# WKUPAON_PRM register map
Vendor: Texas Instruments
Peripheral module from a debugger description file (folder omap5430_ES2_PUBLIC).
Registers are 32-bit, access not given, reset 0x1 unless marked. A register's access mark holds for its fields unless they carry their own. Offsets are as the file gives them; lines under a group give offsets from that group; [hi:lo] are bit positions; {n}, {i} and the like mark numbered series; 'fields as' and 'values as' point back to an identical list; <NAME> marks a mode.

## WKUPAON_PRM
0x24 RM_WKUPAON_L4_WKUP_CONTEXT — This register contains dedicated L4_WKUP context statuses. [warm reset insensitive]
  [0] LOSTCONTEXT_DFF — Specify if DFF-based context has been lost due to a previous power transition or other reset source. (set upon assertion of WKUPAON_RST signal) (access RW W1toClr)
    0=Maintained (Context has been maintained); 1=Lost (Context has been lost)
0x30 PM_WKUPAON_WD_TIMER2_WKDEP access per field reset 0x0 — This register controls wakeup dependency based on WD_TIMER2 service requests.
  [0] WKUPDEP_WD_TIMER2_MPU rw — Wakeup dependency from WD_TIMER2 module (SWakeup signal) towards MPU + L3_MAIN1 domains
    0=Disabled (Dependency is disabled); 1=Enabled (Dependency is enabled)
0x34 RM_WKUPAON_WD_TIMER2_CONTEXT — This register contains dedicated WD_TIMER2 context statuses. [warm reset insensitive]
  fields as RM_WKUPAON_L4_WKUP_CONTEXT
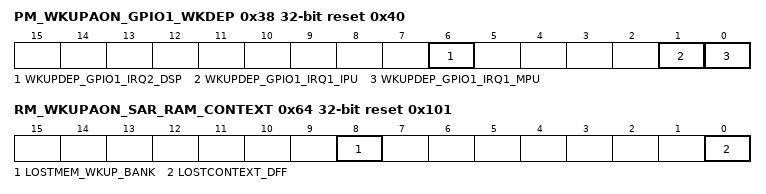
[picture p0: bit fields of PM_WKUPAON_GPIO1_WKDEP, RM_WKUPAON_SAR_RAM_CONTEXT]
0x38 PM_WKUPAON_GPIO1_WKDEP access per field reset 0x40 — This register controls wakeup dependency based on GPIO1 service requests.
  [6] WKUPDEP_GPIO1_IRQ2_DSP rw — Wakeup dependency from GPIO1 module (POINTRSWAKEUP2 signal) towards DSP + L3_MAIN1 domains
    0=Enabled (Dependency is disabled); 1=Enabled (Dependency is enabled)
  [1] WKUPDEP_GPIO1_IRQ1_IPU rw — Wakeup dependency from GPIO1 module (POINTRSWAKEUP1 signal) module towards IPU + L3_MAIN2 + L3_MAIN1 domains
    values as PM_WKUPAON_WD_TIMER2_WKDEP.WKUPDEP_WD_TIMER2_MPU
  [0] WKUPDEP_GPIO1_IRQ1_MPU rw — Wakeup dependency from GPIO1 module (POINTRSWAKEUP1 signal) towards MPU + L3_MAIN1 domains
    values as PM_WKUPAON_WD_TIMER2_WKDEP.WKUPDEP_WD_TIMER2_MPU
0x3C RM_WKUPAON_GPIO1_CONTEXT — This register contains dedicated GPIO1 context statuses. [warm reset insensitive]
  fields as RM_WKUPAON_L4_WKUP_CONTEXT
0x40 PM_WKUPAON_TIMER1_WKDEP access per field — This register controls wakeup dependency based on TIMER1 service requests.
  [0] WKUPDEP_TIMER1_MPU rw — Wakeup dependency from TIMER1 module (SWakeup signal) towards MPU + L3_MAIN1 domains
    0=Dependency_is_disabled; 1=Enabled (Dependency is enabled)
0x44 RM_WKUPAON_TIMER1_CONTEXT — This register contains dedicated TIMER1 context statuses. [warm reset insensitive]
  fields as RM_WKUPAON_L4_WKUP_CONTEXT
0x54 RM_WKUPAON_COUNTER_32K_CONTEXT — This register contains dedicated COUNTER_32K context statuses.This bit-field is only sensitive to the external power-on reset (SYS_PWRON_RST reset line)
  [0] LOSTCONTEXT_DFF — Specify if DFF-based context has been lost due to a previous power transition or other reset source. (set upon assertion of WKUPAON_SYS_PWRON_RST signal) (access RW W1toClr)
    values as RM_WKUPAON_L4_WKUP_CONTEXT.LOSTCONTEXT_DFF
0x64 RM_WKUPAON_SAR_RAM_CONTEXT reset 0x101 — This register contains dedicated SAR_RAM context statuses. [warm reset insensitive]
  [8] LOSTMEM_WKUP_BANK — Specify if memory-based context in WKUP_BANK memory bank has been lost due to a previous global cold reset. (access RW W1toClr)
    values as RM_WKUPAON_L4_WKUP_CONTEXT.LOSTCONTEXT_DFF
  [0] LOSTCONTEXT_DFF — Specify if DFF-based context has been lost due to a previous power transition or other reset source. (set upon assertion of WKUPAON_RST signal) (access RW W1toClr)
    values as RM_WKUPAON_L4_WKUP_CONTEXT.LOSTCONTEXT_DFF
0x78 PM_WKUPAON_KBD_WKDEP access per field — This register controls wakeup dependency based on KBD service requests.
  [0] WKUPDEP_KBD_MPU rw — Wakeup dependency from KBD module (SWakeup signal) towards MPU + L3_MAIN1 domains
    values as PM_WKUPAON_GPIO1_WKDEP.WKUPDEP_GPIO1_IRQ2_DSP
0x7C RM_WKUPAON_KBD_CONTEXT — This register contains dedicated KBD context statuses. [warm reset insensitive]
  fields as RM_WKUPAON_L4_WKUP_CONTEXT
